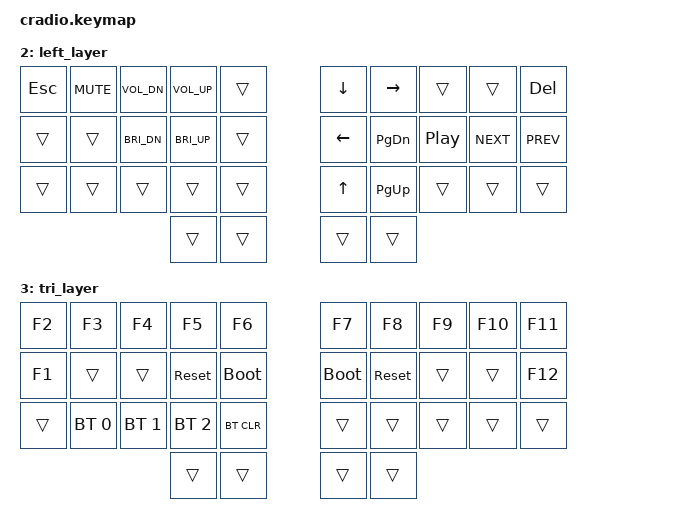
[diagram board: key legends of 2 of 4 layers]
// Copyright (c) 2022 The ZMK Contributors
// SPDX-License-Identifier: MIT

#include <behaviors.dtsi>
#include <dt-bindings/zmk/keys.h>
#include <dt-bindings/zmk/bt.h>

// Home row mods macro
#define HRML(k1,k2,k3,k4) &ht LSHFT k1  &ht LALT k2  &ht LCTRL k3  &ht LGUI k4
#define HRMR(k1,k2,k3,k4) &ht RGUI k1  &ht RCTRL k2  &ht RALT k3  &ht RSHFT k4

/ {
    behaviors {
        ht: hold_tap {
            compatible = "zmk,behavior-hold-tap";
            #binding-cells = <2>;
            flavor = "tap-preferred";
            tapping-term-ms = <220>;
            quick-tap-ms = <150>;
            require-prior-idle-ms = <100>;
            bindings = <&kp>, <&kp>;
        };
    };

    conditional_layers {
        compatible = "zmk,conditional-layers";
        tri_layer {
            if-layers = <1 2>;
            then-layer = <3>;
        };
    };

    keymap {
        compatible = "zmk,keymap";
        default_layer {
            bindings = <
        //╭──────────┬──────────┬──────────┬──────────┬──────────╮   ╭──────────┬──────────┬──────────┬──────────┬──────────╮
        //│  Q       │  W       │  F       │  P       │  G       │   │  J       │  L       │  U       │  Y       │ BACKSLASH│
            &kp Q      &kp W      &kp F      &kp P      &kp G          &kp J      &kp L      &kp U      &kp Y      &kp BSLH
        //├──────────┼──────────┼──────────┼──────────┼──────────┤   ├──────────┼──────────┼──────────┼──────────┼──────────┤
        //│  A       │  R       │  S       │  T       │  D       │   │  H       │  N       │  E       │  I       │  O       │
            HRML(A,        R,         S,         T)     &kp D          &kp H      HRMR(N,        E,         I,        O)
        //├──────────┼──────────┼──────────┼──────────┼──────────┤   ├──────────┼──────────┼──────────┼──────────┼──────────┤
        //│  Z       │  X       │  C       │  V       │  B       │   │  K       │  M       │ , <      │ . >      │ / ?      │
            &kp Z      &kp X      &kp C      &kp V      &kp B          &kp K      &kp M      &kp COMMA  &kp DOT    &kp FSLH
        //╰──────────┴──────────┴──────────┼──────────┼──────────┤   ├──────────┼──────────┼──────────┴──────────┴──────────╯
                                            &lt 1 TAB   &kp BSPC     &kp SPACE  &lt 2 ENTER
        //                                 ╰──────────┴──────────╯   ╰──────────┴──────────╯
            >;
        };

       right_layer {
            bindings = <
        //╭──────────┬──────────┬──────────┬──────────┬──────────╮   ╭──────────┬──────────┬──────────┬──────────┬──────────╮
        //│ `        │          │          │          │          │   │          │    '"    │ -_       │ +=       │  ;       │
            &kp GRAVE    &trans      &trans     &trans     &trans      &trans    &kp SQT  &kp MINUS &kp EQUAL   &kp SEMI
        //├──────────┼──────────┼──────────┼──────────┼──────────┤   ├──────────┼──────────┼──────────┼──────────┼──────────┤
        //│ 1        │  2       │  3       │  4       │    5     │   │ 6        │ 7        │ 8        │ 9        │  0       │
            HRML( N1   , N2     , N3     ,     N4    ) &kp N5         &kp N6    HRMR( N7,      N8,        N9,        N0)
        //├──────────┼──────────┼──────────┼──────────┼──────────┤   ├──────────┼──────────┼──────────┼──────────┼──────────┤
        //│ CAPS     │          │          │          │          │   │          │          │          │    [{    │  ]}      │
           &caps_word  &trans     &trans     &trans     &trans          &trans     &trans     &trans     &kp LBKT   &kp RBKT
        //╰──────────┴──────────┴──────────┼──────────┼──────────┤   ├──────────┼──────────┼──────────┴──────────┴──────────╯
                                             &trans     &trans        &trans     &trans
        //                                 ╰──────────┴──────────╯   ╰──────────┴──────────╯
            >;
        };


       left_layer {
            bindings = <
        //╭──────────┬──────────┬──────────┬──────────┬──────────╮   ╭──────────┬──────────┬──────────┬──────────┬──────────╮
        //│ ESCAPE   │ MUTE     │ VOL DOWN │ VOL UP   │              │ DOWN     │   RIGHT  │          │          │  DELETE  │
            &kp ESC   &kp C_MUTE &kp C_VOL_DN &kp C_VOL_UP &trans     &kp DOWN    &kp RIGHT  &trans      &trans     &kp DEL  
        //├──────────┼──────────┼──────────┼──────────┼──────────┤   ├──────────┼──────────┼──────────┼──────────┼──────────┤
        //│          │          │ BRT DOWN |  BRT UP  │          │   │  LEFT    │  PG DN   │  PLAY    │  NEXT    │ PREV     │
           &trans     &trans     &kp C_BRI_DN &kp C_BRI_UP &trans       &kp LEFT  &kp PG_DN  &kp C_PP   &kp C_NEXT &kp C_PREV
        //├──────────┼──────────┼──────────┼──────────┼──────────┤   ├──────────┼──────────┼──────────┼──────────┼──────────┤
        //│          │          │          │          │          │   │   UP     │  PG UP   │          │          │          │
            &trans    &trans      &trans      &trans     &trans        &kp UP    &kp PG_UP   &trans      &trans     &trans
        //╰──────────┴──────────┴──────────┼──────────┼──────────┤   ├──────────┼──────────┼──────────┴──────────┴──────────╯
                                             &trans     &trans         &trans     &trans
        //                                 ╰──────────┴──────────╯   ╰──────────┴──────────╯
            >;
        };

        tri_layer {
            bindings = <
        //╭──────────┬──────────┬──────────┬──────────┬──────────╮   ╭──────────┬──────────┬──────────┬──────────┬──────────╮
        //│ F2       │    F3    │   F4     │    F5    │  F6      │   │F7        │ F8       │ F9       │   F10     │  F11     │
           &kp F2     &kp F3      &kp F4    &kp F5      &kp F6          &kp F7     &kp F8    &kp F9     &kp F10    &kp F11
        //├──────────┼──────────┼──────────┼──────────┼──────────┤   ├──────────┼──────────┼──────────┼──────────┼──────────┤
        //│  F1      │          │          │  RESET   │BOOTLOADER│   │BOOTLOADER| RESET    │          │          │   F12    │
          &kp F1     &trans     &trans    &sys_reset &bootloader      &bootloader &sys_reset  &trans   &trans    &kp F12
        //├──────────┼──────────┼──────────┼──────────┼──────────┤   ├──────────┼──────────┼──────────┼──────────┼──────────┤
        //│          ││PROFILE 0 │PROFILE 1 │PROFILE 2 │CLEAR BT │   │          │          │          │
            &trans     &bt BT_SEL 0 &bt BT_SEL 1 &bt BT_SEL 2 &bt BT_CLR   &trans     &trans     &trans     &trans     &trans
        //╰──────────┴──────────┴──────────┼──────────┼──────────┤   ├──────────┼──────────┼──────────┴──────────┴──────────╯
                                             &trans     &trans         &trans     &trans
        //                                 ╰──────────┴──────────╯   ╰──────────┴──────────╯
            >;
        };
    };
};
